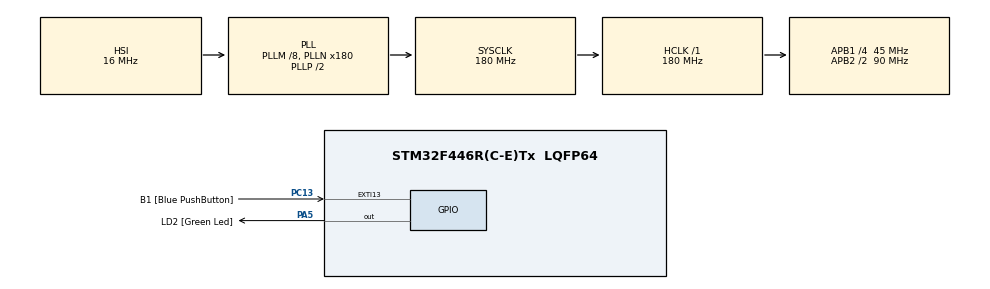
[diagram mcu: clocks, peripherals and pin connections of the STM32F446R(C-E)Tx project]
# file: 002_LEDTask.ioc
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Mcu.Family=STM32F4
Mcu.Name=STM32F446R(C-E)Tx
Mcu.Package=LQFP64
NVIC.PriorityGroup=NVIC_PRIORITYGROUP_4
NVIC.TIM6_DAC_IRQn=true\:0\:0\:false\:false\:true\:false\:true\:true
NVIC.TimeBase=TIM6_DAC_IRQn
NVIC.TimeBaseIP=TIM6
PA13.GPIO_Label=TMS
PA13.Signal=SYS_JTMS-SWDIO
PA14.GPIO_Label=TCK
PA14.Signal=SYS_JTCK-SWCLK
PA2.GPIO_Label=USART_TX
PA2.Signal=USART2_TX
PA3.GPIO_Label=USART_RX
PA3.Signal=USART2_RX
PA5.GPIO_Label=LD2 [Green Led]
PA5.Signal=GPIO_Output
PB3.GPIO_Label=SWO
PB3.Signal=SYS_JTDO-SWO
PC13.GPIO_Label=B1 [Blue PushButton]
PC13.GPIO_ModeDefaultEXTI=GPIO_MODE_IT_FALLING
PC13.Signal=GPXTI13
PC14-OSC32_IN.Signal=RCC_OSC32_IN
PC15-OSC32_OUT.Signal=RCC_OSC32_OUT
PH0-OSC_IN.Signal=RCC_OSC_IN
PH1-OSC_OUT.Signal=RCC_OSC_OUT
ProjectManager.HeapSize=0x200
ProjectManager.StackSize=0x400
ProjectManager.TargetToolchain=STM32CubeIDE
RCC.AHBFreq_Value=180000000
RCC.APB1CLKDivider=RCC_HCLK_DIV4
RCC.APB1Freq_Value=45000000
RCC.APB1TimFreq_Value=90000000
RCC.APB2CLKDivider=RCC_HCLK_DIV2
RCC.APB2Freq_Value=90000000
RCC.APB2TimFreq_Value=180000000
RCC.CortexFreq_Value=180000000
RCC.FLatency-AdvancedSettings=FLASH_LATENCY_5
RCC.HCLKFreq_Value=180000000
RCC.HSE_VALUE=8000000
RCC.HSI_VALUE=16000000
RCC.LSE_VALUE=32768
RCC.PLLM=8
RCC.PLLN=180
RCC.SYSCLKFreq_VALUE=180000000
RCC.SYSCLKSource=RCC_SYSCLKSOURCE_PLLCLK
RCC.USBFreq_Value=180000000
RCC.VCOOutputFreq_Value=360000000
VP_SYS_VS_tim6.Mode=TIM6
board=NUCLEO-F446RE

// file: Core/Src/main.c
/* USER CODE BEGIN Header */
/**
  ******************************************************************************
  * @file           : main.c
  * @brief          : Main program body
  ******************************************************************************
  * @attention
  *
  * Copyright (c) 2023 STMicroelectronics.
  * All rights reserved.
  *
  * This software is licensed under terms that can be found in the LICENSE file
  * in the root directory of this software component.
  * If no LICENSE file comes with this software, it is provided AS-IS.
  *
  ******************************************************************************
  */
/* USER CODE END Header */
#include "main.h"

/* USER CODE BEGIN Includes */
// #include "FreeRTOSConfig.h"
#include "FreeRTOS.h"
#include "task.h"
#include <string.h>
#include <stdio.h>
#include <stdint.h>
/* USER CODE END Includes */

/* USER CODE BEGIN PV */
#define DWT_CTRL_CNT *((volatile uint32_t*)0xE0001000)
TaskHandle_t greenLedTaskHandle;
TaskHandle_t tickCountingTaskHandle;
TaskHandle_t sendDataToPCHandle;
/* USER CODE END PV */

void SystemClock_Config(void);
static void MX_GPIO_Init(void);
/* USER CODE BEGIN PFP */
static void greenLedTask_handler(void* parameters);
static void tickCountingTask_handler(void* parameters);

extern  void SEGGER_UART_init(uint32_t);
/* USER CODE END PFP */

/* USER CODE BEGIN 0 */
static void greenLedTask_handler(void *parameters) {
	char msg[100];
	int count = 1;
	int count2 = 0;

	BaseType_t notifyResult = 0u;
	TickType_t prevWakeTime = xTaskGetTickCount();
	TickType_t frequency = 200;

	 while(1) {
		 notifyResult = xTaskNotifyWaitIndexed(0, 0, 0, NULL, 2000); //(0, 0, 0, 2000);

		 if (notifyResult == pdTRUE) {
		 	snprintf(msg,100,"%s\n", "Notification at greenLED task received\n");
		 	SEGGER_SYSVIEW_PrintfTarget(msg);
		 }
		//snprintf(msg,100,"%s\n", (char*)parameters);
		//SEGGER_SYSVIEW_PrintfTarget(msg);
		if (count == 6) {
			count = 1;
		}

		count2 = count;
		while (count2 > 0) {
			HAL_GPIO_TogglePin(GPIOA, greenLed);

			// using fixed delay span
			// vTaskDelay(pdMS_TO_TICKS(200));

			// using fixed task wake up
			vTaskDelayUntil(&prevWakeTime, frequency);

			HAL_GPIO_TogglePin(GPIOA, greenLed);

			// using fixed delay span
		    // vTaskDelay(pdMS_TO_TICKS(200));

			// using fixed task wake up
			vTaskDelayUntil(&prevWakeTime, frequency);
			count2--;
		}
		count++;
		// HAL_GPIO_TogglePin(GPIOA, greenLed);
		HAL_GPIO_WritePin(GPIOA, greenLed, 0u);
		//vTaskDelay(pdMS_TO_TICKS(2000));
		vTaskDelayUntil(&prevWakeTime, (frequency*10u));

		// printf("%s\n", (char *)parameters);
		// taskYIELD();
		xTaskNotifyIndexed(tickCountingTaskHandle, 0, 0, eNoAction); //(tickCountingTaskHandle, 0, 0);
	 }
}

static void sendDataToPC_handler(void *parameters) {
	char msg[100];
	char time[50];
	uint32_t notificationVal;
	while(1) {
		// printf("%s\n", (char *)parameters);
		// snprintf(msg,100,"%s\n", (char*)parameters);
		// SEGGER_SYSVIEW_PrintfTarget(msg);
		// taskYIELD();
		if ((xTaskNotifyWaitIndexed(1, 0, 0, &notificationVal, 2000)) == pdTRUE) {
			snprintf(msg, 100, "%s", (char*)parameters);

			snprintf(time, 50, "%lu\n", notificationVal);

			strcat(msg, time);

			SEGGER_SYSVIEW_PrintfTarget(msg);

			// xTaskNotifyIndexed(tickCountingTaskHandle, 1, 0, eNoAction);
			xTaskGenericNotify( tickCountingTaskHandle, 1, 0, eNoAction, NULL );
		} else {
			// while (1);
		}

	}
}

static void tickCountingTask_handler(void *parameters) {
	char msg[100];
	uint32_t secElapsed = 0u;
	uint32_t currSysTimeMS = xTaskGetTickCount() * (1/configTICK_RATE_HZ) * 1000;
	uint32_t prevSysTimeMS = currSysTimeMS;
	while(1) {
		// printf("%s\n", (char *)parameters);
		// snprintf(msg,100,"%s\n", (char*)parameters);
		// SEGGER_SYSVIEW_PrintfTarget(msg);
		// taskYIELD();
		if ((currSysTimeMS - prevSysTimeMS) >= 1000) {
			prevSysTimeMS = currSysTimeMS;
			secElapsed++;
			xTaskNotifyIndexed(sendDataToPCHandle, 1, secElapsed, eSetValueWithOverwrite);
			if ((xTaskNotifyWaitIndexed(1, 0, 0, NULL, 2000)) == pdFALSE) {
				while (1);
			}
		}
		xTaskNotifyIndexed(greenLedTaskHandle, 0, 0, eNoAction); //(greenLedTaskHandle, 0, 0);

		BaseType_t notifyResult = xTaskNotifyWaitIndexed(0, 0, 0, NULL, 2000); //(0, 0, 0, 2000);

		if (notifyResult == pdTRUE) {
			snprintf(msg,100,"%s\n", "Notification at tickcount received\n");
			SEGGER_SYSVIEW_PrintfTarget(msg);
		}

		currSysTimeMS = xTaskGetTickCount();//  * (1/configTICK_RATE_HZ) * 1000;
	}
}
/* USER CODE END 0 */

int main(void)
{
  /* USER CODE BEGIN 1 */

	BaseType_t status;

  /* USER CODE END 1 */

  /* MCU Configuration--------------------------------------------------------*/

  /* Reset of all peripherals, Initializes the Flash interface and the Systick. */
  HAL_Init();

  /* Configure the system clock */
  SystemClock_Config();

  /* Initialize all configured peripherals */
  MX_GPIO_Init();
  /* USER CODE BEGIN 2 */
  // enable cycle counter register to have proper time stamps in SysVIew
  DWT_CTRL_CNT |= (1 << 0);

  SEGGER_UART_init(500000);

  // configure and call sysview apis to record
  SEGGER_SYSVIEW_Conf();
  // SEGGER_SYSVIEW_Start();

  // create tasks
  status = xTaskCreate(greenLedTask_handler, "greenLedTask", 200, "Hello from greenLedTask", 2, &greenLedTaskHandle);
  configASSERT(status == pdPASS);

  status = xTaskCreate(tickCountingTask_handler, "tickCountingTask", 200, "Hello from tickCountingTask", 2, &tickCountingTaskHandle);
  configASSERT(status == pdPASS);

  status = xTaskCreate(sendDataToPC_handler, "sendDataToPCTask", 200, "Hello from sendDataToPCTask: ", 2, &sendDataToPCHandle);
    configASSERT(status == pdPASS);

  // start scheduler to run tasks
  vTaskStartScheduler();

  /* USER CODE END 2 */

  /* Infinite loop */
  while (1)
  {

  }
}

void SystemClock_Config(void)
{
  RCC_OscInitTypeDef RCC_OscInitStruct = {0};
  RCC_ClkInitTypeDef RCC_ClkInitStruct = {0};

  /** Configure the main internal regulator output voltage
  */
  __HAL_RCC_PWR_CLK_ENABLE();
  __HAL_PWR_VOLTAGESCALING_CONFIG(PWR_REGULATOR_VOLTAGE_SCALE1);

  /** Initializes the RCC Oscillators according to the specified parameters
  * in the RCC_OscInitTypeDef structure.
  */
  RCC_OscInitStruct.OscillatorType = RCC_OSCILLATORTYPE_HSI;
  RCC_OscInitStruct.HSIState = RCC_HSI_ON;
  RCC_OscInitStruct.HSICalibrationValue = RCC_HSICALIBRATION_DEFAULT;
  RCC_OscInitStruct.PLL.PLLState = RCC_PLL_ON;
  RCC_OscInitStruct.PLL.PLLSource = RCC_PLLSOURCE_HSI;
  RCC_OscInitStruct.PLL.PLLM = 8;
  RCC_OscInitStruct.PLL.PLLN = 180;
  RCC_OscInitStruct.PLL.PLLP = RCC_PLLP_DIV2;
  RCC_OscInitStruct.PLL.PLLQ = 2;
  RCC_OscInitStruct.PLL.PLLR = 2;
  if (HAL_RCC_OscConfig(&RCC_OscInitStruct) != HAL_OK)
  {
    Error_Handler();
  }

  /** Activate the Over-Drive mode
  */
  if (HAL_PWREx_EnableOverDrive() != HAL_OK)
  {
    Error_Handler();
  }

  /** Initializes the CPU, AHB and APB buses clocks
  */
  RCC_ClkInitStruct.ClockType = RCC_CLOCKTYPE_HCLK|RCC_CLOCKTYPE_SYSCLK
                              |RCC_CLOCKTYPE_PCLK1|RCC_CLOCKTYPE_PCLK2;
  RCC_ClkInitStruct.SYSCLKSource = RCC_SYSCLKSOURCE_PLLCLK;
  RCC_ClkInitStruct.AHBCLKDivider = RCC_SYSCLK_DIV1;
  RCC_ClkInitStruct.APB1CLKDivider = RCC_HCLK_DIV4;
  RCC_ClkInitStruct.APB2CLKDivider = RCC_HCLK_DIV2;

  if (HAL_RCC_ClockConfig(&RCC_ClkInitStruct, FLASH_LATENCY_5) != HAL_OK)
  {
    Error_Handler();
  }
}

static void MX_GPIO_Init(void)
{
  GPIO_InitTypeDef GPIO_InitStruct = {0};

  /* GPIO Ports Clock Enable */
  __HAL_RCC_GPIOC_CLK_ENABLE();
  __HAL_RCC_GPIOH_CLK_ENABLE();
  __HAL_RCC_GPIOA_CLK_ENABLE();
  __HAL_RCC_GPIOB_CLK_ENABLE();

  /*Configure GPIO pin Output Level */
  HAL_GPIO_WritePin(LD2_GPIO_Port, LD2_Pin, GPIO_PIN_RESET);

  /*Configure GPIO pin : B1_Pin */
  GPIO_InitStruct.Pin = B1_Pin;
  GPIO_InitStruct.Mode = GPIO_MODE_IT_FALLING;
  GPIO_InitStruct.Pull = GPIO_NOPULL;
  HAL_GPIO_Init(B1_GPIO_Port, &GPIO_InitStruct);

  /*Configure GPIO pins : USART_TX_Pin USART_RX_Pin */
  GPIO_InitStruct.Pin = USART_TX_Pin|USART_RX_Pin;
  GPIO_InitStruct.Mode = GPIO_MODE_AF_PP;
  GPIO_InitStruct.Pull = GPIO_NOPULL;
  GPIO_InitStruct.Speed = GPIO_SPEED_FREQ_VERY_HIGH;
  GPIO_InitStruct.Alternate = GPIO_AF7_USART2;
  HAL_GPIO_Init(GPIOA, &GPIO_InitStruct);

  /*Configure GPIO pin : LD2_Pin */
  GPIO_InitStruct.Pin = LD2_Pin;
  GPIO_InitStruct.Mode = GPIO_MODE_OUTPUT_PP;
  GPIO_InitStruct.Pull = GPIO_NOPULL;
  GPIO_InitStruct.Speed = GPIO_SPEED_FREQ_LOW;
  HAL_GPIO_Init(LD2_GPIO_Port, &GPIO_InitStruct);

}

void HAL_TIM_PeriodElapsedCallback(TIM_HandleTypeDef *htim)
{
  if (htim->Instance == TIM6) {
    HAL_IncTick();
  }
}

void Error_Handler(void)
{
  __disable_irq();
  while (1)
  {
  }
}
